# MMC1 register map
Vendor: Texas Instruments
Registers are 32-bit, access per field, reset 0x0 unless marked. A register's access mark holds for its fields unless they carry their own. Offsets are as the file gives them; [hi:lo] are bit positions; 'fields as' and 'values as' point back to an identical list.

## MMC1 (part 3 of 3)
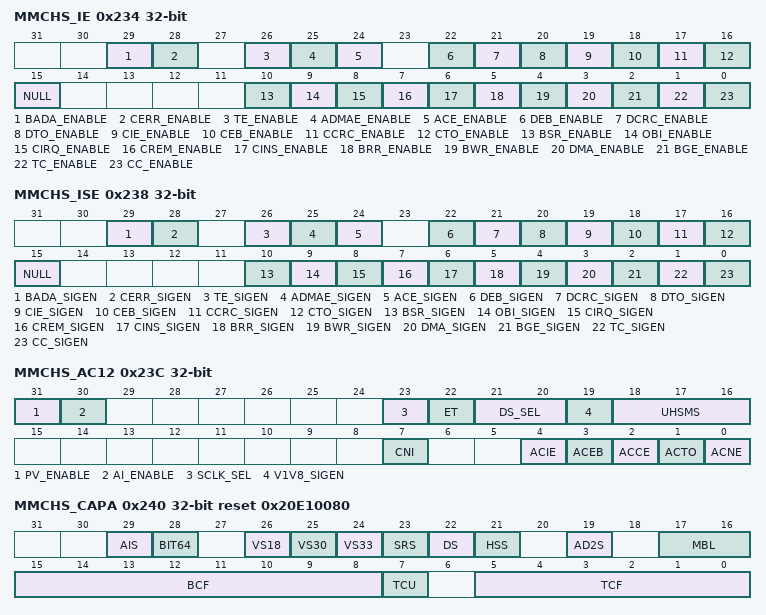
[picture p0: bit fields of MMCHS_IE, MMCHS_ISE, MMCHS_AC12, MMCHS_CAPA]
0x234 MMCHS_IE — Interrupt Status Enable Register This register allows to enable/disable the module to set status bits, on an event-by-event basis. [31:16] = Error Interrupt Status Enable [15:0] = Normal Interrupt Status Enable
  [29] BADA_ENABLE rw — Bad access to data space Status Enable
    0=Masked; 1=Enabled
  [28] CERR_ENABLE rw — Card Error Status Enable
    0=Masked; 1=Enabled
  [26] TE_ENABLE rw — Tuning Error Status Enable
    0=Masked; 1=Enabled
  [25] ADMAE_ENABLE rw — ADMA Error Status Enable
    0=Masked; 1=Enabled
  [24] ACE_ENABLE rw — Auto CMD Error Status Enable
    0=Masked; 1=Enabled
  [22] DEB_ENABLE rw — Data End Bit Error Status Enable
    0=Masked; 1=Enabled
  [21] DCRC_ENABLE rw — Data CRC Error Status Enable
    0=Masked; 1=Enabled
  [20] DTO_ENABLE rw — Data Timeout Error Status Enable
    0=Masked (The data timeout detection is deactivated. The host controller provides the clock to the card until the card sends the data or the transfer is aborted.); 1=Enabled (The data timeout detection is enabled.)
  [19] CIE_ENABLE rw — Command Index Error Status Enable
    0=Masked; 1=Enabled
  [18] CEB_ENABLE rw — Command End Bit Error Status Enable
    0=Masked; 1=Enabled
  [17] CCRC_ENABLE rw — Command CRC Error Status Enable
    0=Masked; 1=Enabled
  [16] CTO_ENABLE rw — Command Timeout Error Status Enable
    0=Masked; 1=Enabled
  [15] NULL ro — Fixed to 0 The host driver shall control error interrupts using the Error Interrupt Signal Enable register. Writes to this bit are ignored
  [10] BSR_ENABLE rw — Boot Status Enable A write to this register when MMCHS_CON[BOOT_ACK] is set to 0x0 is ignored.
    0=Masked; 1=Enabled
  [9] OBI_ENABLE rw — Out-of-Band Status Enable A write to this register when MMCHS_CON[OBIE] is set to '0' is ignored.
    0=Masked; 1=Enabled
  [8] CIRQ_ENABLE rw — Card Status Enable A clear of this bit also clears the corresponding status bit. During 1-bit mode, if the interrupt routine doesn't remove the source of a card interrupt in the SDIO card, the status bit is reasserted when this bit is set to 1.
    0=Masked; 1=Enabled
  [7] CREM_ENABLE rw — Card Removal Status Enable
    0=Masked; 1=Enabled
  [6] CINS_ENABLE rw — Card Insertion Status Enable
    0=Masked; 1=Enabled
  [5] BRR_ENABLE rw — Buffer Read Ready Status Enable
    0=Masked; 1=Enabled
  [4] BWR_ENABLE rw — Buffer Write Ready Status Enable
    0=Masked; 1=Enabled
  [3] DMA_ENABLE rw — DMA Status Enable
    0=Masked; 1=Enabled
  [2] BGE_ENABLE rw — Block Gap Event Status Enable
    0=Masked; 1=Enabled
  [1] TC_ENABLE rw — Transfer Complete Status Enable
    0=Masked; 1=Enabled
  [0] CC_ENABLE rw — Command Complete Status Enable
    0=Masked; 1=Enabled
0x238 MMCHS_ISE — Interrupt Signal Enable Register This register allows to enable/disable the module internal sources of status, on an event-by-event basis. [31:16] = Error Interrupt Signal Enable [15:0] = Normal Interrupt Signal Enable
  [29] BADA_SIGEN rw — Bad access to data space Signal Enable
    0=Masked; 1=Enabled
  [28] CERR_SIGEN rw — Card Error Interrupt Signal Enable
    0=Masked; 1=Enabled
  [26] TE_SIGEN rw — Tuning Error Signal Enable
    0=Masked; 1=Enabled
  [25] ADMAE_SIGEN rw — ADMA Error Signal Enable
    0=Masked; 1=Enabled
  [24] ACE_SIGEN rw — Auto CMD Error Signal Enable
    0=Masked; 1=Enabled
  [22] DEB_SIGEN rw — Data End Bit Error Signal Enable
    0=Masked; 1=Enabled
  [21] DCRC_SIGEN rw — Data CRC Error Signal Enable
    0=Masked; 1=Enabled
  [20] DTO_SIGEN rw — Data Timeout Error Signal Enable
    0=Masked; 1=Enabled
  [19] CIE_SIGEN rw — Command Index Error Signal Enable
    0=Masked; 1=Enabled
  [18] CEB_SIGEN rw — Command End Bit Error Signal Enable
    0=Masked; 1=Enabled
  [17] CCRC_SIGEN rw — Command CRC Error Signal Enable
    0=Masked; 1=Enabled
  [16] CTO_SIGEN rw — Command timeout Error Signal Enable
    0=Masked; 1=Enabled
  [15] NULL ro — Fixed to 0 The host driver shall control error interrupts using the Error Interrupt Signal Enable register. Writes to this bit are ignored
  [10] BSR_SIGEN rw — Boot Status Signal Enable A write to this register when MMCHS_CON[BOOT_ACK] is set to 0x0 is ignored.
    0=Masked; 1=Enabled
  [9] OBI_SIGEN rw — Out-Of-Band Interrupt Signal Enable A write to this register when MMCHS_CON[OBIE] is set to '0' is ignored.
    0=Masked; 1=Enabled
  [8] CIRQ_SIGEN rw — Card Interrupt Signal Enable
    0=Masked; 1=Enabled
  [7] CREM_SIGEN rw — Card Removal Signal Enable
    0=Masked; 1=Enabled
  [6] CINS_SIGEN rw — Card Insertion Signal Enable
    0=Masked; 1=Enabled
  [5] BRR_SIGEN rw — Buffer Read Ready Signal Enable
    0=Masked; 1=Enabled
  [4] BWR_SIGEN rw — Buffer Write Ready Signal Enable
    0=Masked; 1=Enabled
  [3] DMA_SIGEN rw — DMA Interrupt Signal Enable
    0=Masked; 1=Enabled
  [2] BGE_SIGEN rw — Black Gap Event Signal Enable
    0=Masked; 1=Enabled
  [1] TC_SIGEN rw — Transfer Completed Status Enable
    0=Masked; 1=Enabled
  [0] CC_SIGEN rw — Command Complete Status Enable
    0=Masked; 1=Enabled
0x23C MMCHS_AC12 — Host Control 2 Register and Auto CMD Error Status Register This register is used to indicate CMD12 response error of Auto CMD12 and CMD23 response error of Auto CMD23. The Host driver can determine what kind of Auto CMD12 / CMD23 errors occur by this register. Auto CMD23 errors are indicated only in bits[4:1]. Bits[7:0] are valid only when the [3:2] ACEN bitfield is configured to enable Auto CMD and the Auto CMD Error bit ([24]ACE) is set.
  [31] PV_ENABLE rw — Preset Value Enable Host Controller Version 3.00 supports this bit. As the operating SDCLK frequency and I/O driver strength depend on the Host System implementation, it is difficult to determine these parameters in the Standard Host Driver. When Preset Value Enable is set, automatic SDCLK frequency generation and driver strength selection is performed without considering system specific conditions. This bit enables the functions defined in the Preset Value registers, see, . If this bit is set to 0, MMCHS_SYSCTL[15:6] CLKD, MMCHS_SYSCTL[5] CGS and MMCHS_AC12[21:20] DS_SEL are set by Host Driver. If this bit is set to 1, MMCHS_SYSCTL[15:6] CLKD, MMCHS_SYSCTL[5] CGS and MMCHS_AC12[21:20] DS_SEL are set by Host Controller as specified in the Preset Value registers, see, .
    0=Disabled (SDCLK and Driver Strength (DS_SEL) are controlled by Host Driver.); 1=Enabled (Automatic Selection by Preset Value are Enabled.)
  [30] AI_ENABLE rw — Asynchronous Interrupt Enable This bit can be set to 1 if a card supports asynchronous interrupts and MMCHS_CAPA[29] AIS is set to 1. Asynchronous interrupt is effective when DAT[1] interrupt is used in 4-bit SD mode (and zero is set to Interrupt Pin Select in the Shared Bus Control register). If this bit is set to 1, the Host Driver can stop the SDCLK during asynchronous interrupt period to save power. During this period, the Host Controller continues to deliver the Card Interrupt to the host when it is asserted by the Card.
    0=Disabled; 1=Enabled
  [23] SCLK_SEL rw — Sampling Clock Select Host Controller uses this bit to select sampling clock to receive CMD and DAT. This bit is set by tuning procedure and valid after the completion of tuning (when MMCHS_AC12[22] ET is cleared). Setting 1 means that tuning is completed successfully and setting 0 means that tuning is failed. Writing 1 to this bit is meaningless and ignored. A tuning circuit is reset by writing to 0. This bit can be cleared with setting MMCHS_AC12[22] ET. Once the tuning circuit is reset, it will take time to complete tuning sequence. Therefore, Host Driver should keep this bit to 1 to perform re-tuning sequence to compete re-tuning sequence in a short time. Change of this bit is not allowed while the Host Controller is receiving response or a read data block.
    0=Fixed clock is used to sample data; 1=Tuned clock is used to sample data
  [22] ET rw — Execute Tuning This bit is set to 1 to start tuning procedure and automatically cleared when tuning procedure is completed. The result of tuning is indicated to MMCHS_AC12[23] SCLK_SEL. Tuning procedure is aborted by writing 0. This is Read-Write with automatic clear register
    0=Completed (Not Tuned or Tuning Completed); 1=Execute Tuning
  [21:20] DS_SEL rw — Driver Strength Select Host Controller output driver in 1.8V signaling is selected by this bit. In 3.3V signaling, this field is not effective. This field can be set depending on Driver Type A, C and D support bits (DTA, DTC and DTD respectively) in the MMCHS_CAPA2 register. This bit depends on setting of Preset Value Enable. If Preset Value Enable = 0, this field is set by Host Driver. If Preset Value Enable = 1, this field is automatically set by a value specified in the one of Preset Value registers, see, .
    0=DTB (Driver Type B is selected (Default)); 1=DTA (Driver Type A is selected); 3=DTD (Driver Type D is selected); 2=DTC (Driver Type C is selected)
  [19] V1V8_SIGEN rw — 1.8V Signaling Enable This bit controls voltage regulator for I/O cell. 3.3V is supplied to the card regardless of signaling voltage. Setting this bit from 0 to 1 starts changing signal voltage from 3.3V to 1.8V. 1.8V regulator output shall be stable within 5ms. Host Controller clears this bit if switching to 1.8V signaling fails. Clearing this bit from 1 to 0 starts changing signal voltage from 1.8V to 3.3V. 3.3V regulator output shall be stable within 5ms. Host Driver can set this bit to 1 when Host Controller supports 1.8V signaling (One of support bits is set to 1: SDR50, SDR104 or DDR50 in MMCHS_CAPA2 register) and the card or device supports UHS-I (S18A=1. Refer to Bus Signal Voltage Switch Sequence in the Physical Layer Specification Version 3.0x).
    0=3V3 (3.3V Signaling); 1=1V8 (1.8V Signaling)
  [18:16] UHSMS rw — UHS Mode Select This field is used to select one of UHS-I modes or eMMC HS200 mode and is effective when 1.8V Signaling Enable is set to 1. If MMCHS_AC12[31] PV_ENABLE is set to 1, Host Controller sets MMCHS_SYSCTL[15:6] CLKD, MMCHS_SYSCTL[5] CGS and MMCHS_AC12[21:20] DS_SEL according to Preset Value registers, see, . In this case, one of preset value registers is selected by this field. Host Driver needs to reset MMCHS_SYSCTL[2] CEN before changing this field to avoid generating clock glitch. After setting this field, Host Driver sets MMCHS_SYSCTL[2] CEN again. When SDR50, SDR104 or DDR50 is selected for SDIO card, interrupt detection at the block gap shall not be used. Read Wait timing is changed for these modes. Refer to the SDIO Specification Version 3.00 for more detail.
    0=SDR12; 1=SDR25; 2=SDR50; 3=SDR104_HS200; 4=DDR50
  [7] CNI ro — Command Not Issued By Auto CMD12 Error Setting this bit to 1 means CMD_wo_DAT is not executed due to an Auto CMD12 Error (D04-D01) in this register. This bit is set to 0 when Auto CMD Error is generated by Auto CMD23.
    1=CmdNI (Command not issued); 0=No error
  [4] ACIE ro — Auto CMD Index Error - For Auto CMD12 and Auto CMD23 This bit is set if the Command Index error occurs in response to a command.
    1=Err (Error); 0=No error
  [3] ACEB ro — Auto CMD End Bit Error - For Auto CMD12 and Auto CMD23 This bit is set when detecting that the end bit of command response is 0.
    1=Err (End bit Error Generated); 0=No error
  [2] ACCE ro — Auto CMD CRC Error - For Auto CMD12 and Auto CMD23 This bit is set when detecting a CRC error in the command response.
    1=Err (CRC Error Generated); 0=No error
  [1] ACTO ro — Auto CMD Timeout Error - For Auto CMD12 and Auto CMD23 This bit is set if no response is returned within 64 SDCLK cycles from the end bit of command. If this bit is set to1, the other error status bits (D04-D02) are meaningless.
    1=TimeOut (Auto CMD Time Out); 0=No error
  [0] ACNE ro — Auto CMD12 Not Executed If memory multiple block data transfer is not started due to command error, this bit is not set because it is not necessary to issue Auto CMD12. Setting this bit to 1 means the Host Controller cannot issue Auto CMD12 to stop memory multiple block data transfer due to some error. If this bit is set to 1, other error status bits (D04-D01) are meaningless. This bit is set to 0 when Auto CMD Error is generated by Auto CMD23.
    1=NotExe (Auto CMD12 Not Executed); 0=Exe (Auto CMD12 Executed)
0x240 MMCHS_CAPA reset 0x20E10080 — Capabilities Register This register lists the capabilities of the MMC/SD/SDIO host controller.
  [29] AIS ro — Asynchronous Interrupt Support Refer to SDIO Specification Version 3.00 about asynchronous interrupt.
    1=AIS_Sup (Asynchronous Interrupt Supported); 0=AIS_NotSup (Asynchronous Interrupt Not Supported)
  [28] BIT64 ro — 64 Bit System Bus Support Setting 1 to this bit indicates that the Host Controller supports 64-bit address descriptor mode and is connected to 64-bit address system bus.
    1=SysAddr64b (64 bit System bus address); 0=SysAddr32b (32 bit System bus address)
  [26] VS18 rw — Voltage support 1.8V Initialization of this register (via a write access to this register) depends on the system capabilities. The host driver shall not modify this register after the initilaization. This register is only reinitialized by a hard reset (via RESETN signal)
    0=St_1V8NotSup_w (1.8V Not supported); 1=St_1V8Sup_w (1.8V Supported); 1=1V8_Sup_r (1.8V Supported); 0=1V8_NotSup_r (1.8V Not Supported)
  [25] VS30 rw — Voltage support 3.0V Initialization of this register (via a write access to this register) depends on the system capabilities. The host driver shall not modify this register after the initilaization. This register is only reinitialized by a hard reset (via RESETN signal)
    0=St_3V0NotSup_w (3.0V Not supported); 1=St_3V0Sup_w (3.0V Supported); 1=3V0_Sup_r (3.0V Supported); 0=3V0_NotSup_r (3.0V Not Supported)
  [24] VS33 rw — Voltage support 3.3V Initialization of this register (via a write access to this register) depends on the system capabilities. The host driver shall not modify this register after the initilaization. This register is only reinitialized by a hard reset (via RESETN signal)
    0=St_3V3NotSup_w (3.3V Not supported); 1=St_3V3Sup_w (3.3V Supported); 1=3V3_Sup_r (3.3V Supported); 0=3V3_NotSup_r (3.3V Not Supported)
  [23] SRS ro — Suspend/Resume support (SDIO cards only) This bit indicates whether the host controller supports Suspend/Resume functionality.
    1=Supported (The Host controller supports Suspend/Resume functionality.); 0=NotSupported (The Host controller does not Suspend/Resume functionality.)
  [22] DS ro — DMA support This bit indicates that the Host Controller is able to use DMA to transfer data between system memory and the Host Controller directly.
    1=Supported (DMA Supported); 0=NotSupported (DMA Not Supported)
  [21] HSS ro — High speed support This bit indicates that the host controller supports high speed operations and can supply an up-to maximum card frequency.
    1=Supported (High Speed Supported); 0=NotSupported (High Speed Not Supported NOTE: High Speed modes are supported, but)
  [19] AD2S ro — ADMA2 Support This bit indicates whether the Host Controller is capable of using ADMA2. It depends on setting of generic parameter MADMA_EN
    1=ADMA2Supported; 0=ADMA2NotSupported
  [17:16] MBL ro — Maximum block length This value indicates the maximum block size that the host driver can read and write to the buffer in the host controller. This value depends on definition of generic parameter with a max value of 2048 bytes. The host controller supports 512 bytes and 1024 bytes block transfers.
    2=MBL_2_r (2048 bytes); 1=MBL_1_r (1024 bytes); 0=MBL_0_r (512 bytes)
  [15:8] BCF ro — Base Clock Frequency For SD Clock This value indicates the base (maximum) clock frequency for the SD Clock. 8-bit Base Clock Frequency This mode is supported by the Host Controller Version 3.00. Unit values are 1MHz. The supported clock range is 10MHz to 255MHz. FFh : 255MHz .... : ....... 02h : 2MHz 01h : 1MHz 00h : Get information via another method If the real frequency is 16.5MHz, the lager value shall be set 0001 0001b (17MHz) because the Host Driver use this value to calculate the clock divider value (Refer to MMCHS_SYSCTL[15:6] CLKD) and it shall not exceed upper limit of the SD Clock frequency. If these bits are all 0, the Host System has to get information via another method.
    0=OMeth (The value indicating the base (maximum) frequency for the output clock provided to the card is system dependent and is not available in this register. Get the information via another method.)
  [7] TCU ro — Timeout clock unit This bit shows the unit of base clock frequency used to detect Data Timeout Error (MMCHS_STAT[DTO]).
    1=KHz (MHz); 0=MHz (KHz)
  [5:0] TCF ro — Timeout clock frequency The timeout clock frequency is used to detect Data Timeout Error (MMCHS_STAT[DTO]).
    0=OMeth (The timeout clock frequency depends on the frequency of the clock provided to the card. The value of the timeout clock frequency is not available in this register.)
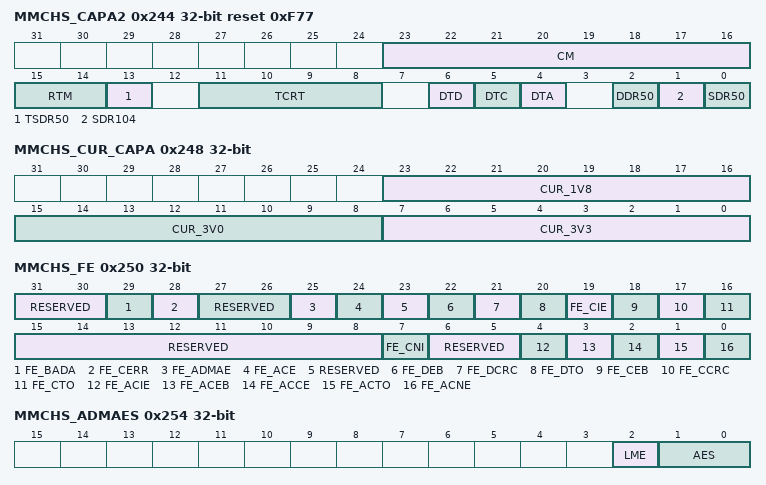
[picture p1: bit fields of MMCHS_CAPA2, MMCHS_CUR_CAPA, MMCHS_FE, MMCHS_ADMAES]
0x244 MMCHS_CAPA2 ro reset 0xF77 — Capabilities 2 Register This register provides the Host Driver with information specific to the Host Controller implementation. The Host Controller may implement these values as fixed or loaded from flash memory during power on initialization. Refer to Software Reset For All in the Software Reset register for loading from flash memory and completion timing control.
  [23:16] CM — Clock Multiplier This field indicates clock multiplier value of programmable clock generator. Refer to MMCHS_SYSCTL [15:0]. Setting 00h means that Host Controller does not support programmable clock generator. 00h : Clock Multiplier is Not Supported 01h : Clock Multiplier M = 2 02h : Clock Multiplier M = 3 .... : ...................... FFh : Clock Multiplier M = 256
  [15:14] RTM — Re-Tuning Modes This field selects re-tuning method and limits the maximum data length. Bit47-46 Re-Tuning Mode Re-Tuning Method Data Length There are two re-tuning timings: Re-Tuning Request controlled by the Host Controller and expiration of a Re-Tuning Timer controlled by the Host Driver. By receiving either timing, the Host Driver executes the re-tuning procedure just before a next command issue. The maximum data length per read/write command is restricted so that re-tuning procedures can be inserted during data transfers. (1) Re-Tuning Mode 1 The host controller does not have any internal logic to detect when the re-tuning needs to be performed. In this case, the Host Driver should maintain all re-tuning timings by using a Re-Tuning Timer. To enable inserting the re-tuning procedure during data transfers, the data length per read/write command shall be limited up to 4 MiB. (2) Re-Tuning Mode 2 The host controller has the capability to indicate the re-tuning timing by Re-Tuning Request during data transfers. Then the data length per read/write command shall be limited up to 4 MiB. During non data transfer, re-tuning timing is determined by either Re-Tuning Request or Re-Tuning Timer. If Re-Tuning Request is used, Re-Tuning Timer should be disabled. (3) Re-Tuning Mode 3 The host controller has the capability to take care of the re-tuning during data transfer (Auto Re-Tuning). Re-Tuning Request shall not be generated during data transfers and there is no limitation to data length per read/write command. During non data transfer, re-tuning timing is determined by either Re-Tuning Request or Re-Tuning Timer. If Re-Tuning Request is used, Re-Tuning Timer should be disabled. Re-Tuning Timer Control Example for Re-Tuning Mode 1 The initial value of re-tuning timer is provided by Timer Count for Re-Tuning field in this register. The timer starts counting by loading the initial value. When the timer expires, the Host Driver marks an expiration flag. On receiving a command request, the Host driver checks the expiration flag. If the expiration flag is set, then the Host Driver should perform the re-tuning procedure before issuing a command. If the expiration flag is not set, then the Host Driver issues a command without performing the re-tuning procedure. Every time the re-tuning procedure is performed, the timer loads the new initial value and the expiration flag is cleared. Re-Tuning Timer Control Example for Re-Tuning Mode 2 and Mode 3 The timer control is almost the same as Re-Tuning Mode 1 except the timer loads the new initial value after data transfer (when receiving Transfer Complete). In case of Mode 3, Timer Count for Re-Tuning is set either smaller value: Tuning effective time after re-tuning procedure or after data transfer. If a Host System goes into power down mode, the Host Driver should stop the re-tuning timer and set the expiration flag to 1 when the Host System resumes from power down mode.
    2=Mode3 (Auto Re-Tuning (for transfer) - Timer and Re-Tuning Request); 1=Mode2 (Timer and Re-Tuning Request - Max data length 4 MiB); 0=Mode1 (Timer - Max data length 4 MiB)
  [13] TSDR50 — Use Tuning for SDR50 If this bit is set to 1, this Host Controller requires tuning to operate SDR50. (Tuning is always required to operate SDR104.)
    1=Required (SDR50 requires tuning.); 0=NotRequired (SDR50 does not require tuning.)
  [11:8] TCRT — Timer Count for Re-Tuning This field indicates an initial value of the Re-Tuning Timer for Re-Tuning Mode 1 to 3. Setting to 0 disables Re-Tuning Timer.
    3=TCRT_3_r (4 seconds); 4=TCRT_4_r (8 seconds); 11=TCRT_11_r (1024 seconds); 15=OtherSource (Get information from other source); 2=TCRT_2_r (2 seconds); 0=Disabled (Re-Tuning Timer disabled); 10=TCRT_10_r (512 seconds); 6=TCRT_6_r (32 seconds); 1=TCRT_1_r (1 second); 8=TCRT_8_r (128 seconds); 7=TCRT_7_r (64 seconds); 9=TCRT_9_r (256 seconds); 5=TCRT_5_r (16 seconds)
  [6] DTD — Driver Type D Support This bit indicates support of Driver Type D for 1.8 Signaling.
    1=Supported (Driver Type D is Supported); 0=NotSupported (Driver Type D is Not Supported.)
  [5] DTC — Driver Type C Support This bit indicates support of Driver Type C for 1.8 Signaling.
    1=Supported (Driver Type C is Supported.); 0=NotSupported (Driver Type C is Not Supported.)
  [4] DTA — Driver Type A Support This bit indicates support of Driver Type A for 1.8 Signaling.
    1=Supported (Driver Type A is Supported.); 0=NotSupported (Driver Type A is Not Supported.)
  [2] DDR50 — DDR50 Support
    1=Supported (DDR50 is Supported.); 0=NotSupported (DDR50 is Not Supported.)
  [1] SDR104 — SDR104 Support SDR104 requires tuning.
    1=Supported (SDR104 is Supported.); 0=NotSupported (SDR104 is Not Supported.)
  [0] SDR50 — SDR50 Support If SDR104 is supported, this bit shall be set to 1. Bit 13 indicates whether SDR50 requires tuning or not.
    1=Supported (SDR50 is Supported.); 0=NotSupported (SDR50 is Not Supported.)
0x248 MMCHS_CUR_CAPA — Maximum Current Capabilities Register This register indicates the maximum current capability for each voltage. The value is meaningful if the voltage support is set in the capabilities register (). Initialization of this register (via a write access to this register) depends on the system capabilities. The host driver shall not modify this register after the initilaization. This register is only reinitialized by a hard reset (via RESETN signal)
  [all] fields
    0=OMeth (The maximum current capability for this voltage is not available. Feature not implemented.)
  [23:16] CUR_1V8 rw — Maximum current for 1.8V
  [15:8] CUR_3V0 rw — Maximum current for 3.0V
  [7:0] CUR_3V3 rw — Maximum current for 3.3V
0x250 MMCHS_FE access not given — Force Event Register for Auto CMD Error Status and Error Interrupt status The Force Event Register is not a physically implemented register. Rather, it is an address at which the Auto CMD Error Status Register () can be written. Writing 1 : set each bit of the Auto CMD Error Status Register Writing 0 : no effect Rather, it is an address at which the Error Interrupt Status register can be written. The effect of a write to this address will be reflected in the Error Interrupt Status Register if the corresponding bit of the Error Interrupt Status Enable Register is set. Writing 1 : set each bit of the Error Interrupt Status Register Writing 0 : no effect Note: By setting this register, the Error Interrupt can be set in the Error Interrupt Status register. In order to generate interrupt signal, both the Error Interrupt Status Enable and Error Interrupt Signal Enable shall be set.
  [31:30] RESERVED — (access NA)
  [29] FE_BADA wo — Force Event Bad access to data space.
    0=NoAction (No effect, No Interrupt.); 1=IntForced (Interrupt Forced)
  [28] FE_CERR wo — Force Event Card error.
    values as FE_BADA
  [27:26] RESERVED — (access NA)
  [25] FE_ADMAE wo — Force Event ADMA Error.
    values as FE_BADA
  [24] FE_ACE wo — Force Event for Auto CMD Error - For Auto CMD12 and Auto CMD23
    values as FE_BADA
  [23] RESERVED — (access NA)
  [22] FE_DEB wo — Force Event Data End Bit error.
    values as FE_BADA
  [21] FE_DCRC wo — Force Event Data CRC Error.
    values as FE_BADA
  [20] FE_DTO wo — Force Event Data Timeout Error.
    values as FE_BADA
  [19] FE_CIE wo — Force Event Command Index Error.
    values as FE_BADA
  [18] FE_CEB wo — Force Event Command End Bit Error.
    values as FE_BADA
  [17] FE_CCRC wo — Force Event Command CRC Error.
    values as FE_BADA
  [16] FE_CTO wo — Command Timeout Error This bit is set automatically when no response is received within 64 clock cycles from the end bit of the command. For commands that reply within 5 clock cycles - the timeout is still detected at 64 clock cycles.
    0=St_un_w (Status bit unchanged); 1=St_rst_w (Status is cleared)
  [15:8] RESERVED — (access NA)
  [7] FE_CNI wo — Force Event Command not issue by Auto CMD12 error
    values as FE_BADA
  [6:5] RESERVED — (access NA)
  [4] FE_ACIE wo — Force Event for Auto CMD Index Error - For Auto CMD12 and Auto CMD23
    values as FE_BADA
  [3] FE_ACEB wo — Force Event Auto CMD End Bit Error
    values as FE_BADA
  [2] FE_ACCE wo — Force Event Auto CMD CRC Error
    values as FE_BADA
  [1] FE_ACTO wo — Force Event Auto CMD Timeout Error
    values as FE_BADA
  [0] FE_ACNE wo — Force Event Auto CMD12 Not Executed
    values as FE_BADA
0x254 MMCHS_ADMAES — ADMA Error Status Register When ADMA Error Interrupt is occurred, the ADMA Error States field in this register holds the ADMA state and the ADMA System Address Register holds the address around the error descriptor. For recovering the error, the Host Driver requires the ADMA state to identify the error descriptor address as follows: ST_STOP: Previous location set in the ADMA System Address register is the error descriptor address ST_FDS: Current location set in the ADMA System Address register is the error descriptor address ST_CADR: This sate is never set because do not generate ADMA error in this state. ST_TFR: Previous location set in the ADMA System Address register is the error descriptor address In case of write operation, the Host Driver should use ACMD22 to get the number of written block rather than using this information, since unwritten data may exist in the Host Controller. The Host Controller generates the ADMA Error Interrupt when it detects invalid descriptor data (Valid=0) at the ST_FDS state. In this case, ADMA Error State indicates that an error occurs at ST_FDS state. The Host Driver may find that the Valid bit is not set in the error descriptor.
  [2] LME rw — ADMA Length Mismatch Error: (1) While Block Count Enable being set, the total data length specified by the Descriptor table is different from that specified by the Block Count and Block Length. (2) Total data length can not be divided by the block length.
    0=NoError; 1=Error
  [1:0] AES rw — ADMA Error State This field indicates the state of ADMA when error occurred during ADMA data transfer. This field will never be 0x2 because ADMA never stops in that state. 0x0: ST_STOP (STOP_ADMA). Previous SYS_ADR is the error descriptor address 0x1: ST_FDS (Fetch Descriptor). Content of current SYS_ADR is the error descriptor address 0x2: Not used. Error never set in this state 0x3: ST_TFR (Transfer Data). Previous SYS_ADR is the error descriptor address
0x258 MMCHS_ADMASAL rw — ADMA System address Low bits
  [31:0] ADMA_A32B — ADMA System address 32 bits.This register holds byte address of executing command of the Descriptor table. 32-bit Address Descriptor uses lower 32-bit of this register. At the start of ADMA, the Host Driver shall set start address of the Descriptor table. The ADMA increments this register address, which points to next line, when every fetching a Descriptor line. When the ADMA Error Interrupt is generated, this register shall hold valid Descriptor address depending on the ADMA state. The Host Driver shall program Descriptor Table on 32-bit boundary and set 32-bit boundary address to this register. ADMA2 ignores lower 2-bit of this register and assumes it to be 00b.
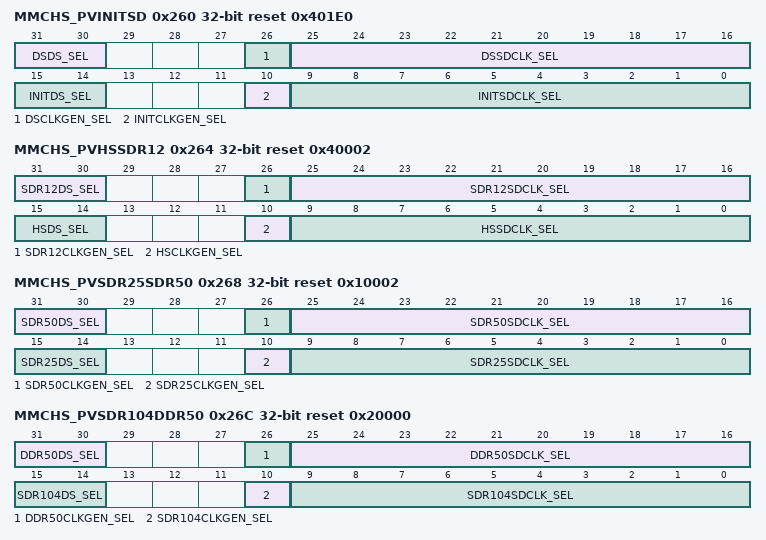
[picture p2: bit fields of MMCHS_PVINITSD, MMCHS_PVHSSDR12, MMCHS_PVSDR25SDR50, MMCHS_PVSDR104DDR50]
0x260 MMCHS_PVINITSD ro reset 0x401E0 — Preset Value for Initialization and Default Speed modes
  [31:30] DSDS_SEL — Driver Strength Select Value - Default Speed mode Driver Strength is supported by 1.8V signaling bus speed modes. This field is meaningless for 3.3V signaling.
    3=DTD (Driver Type D is Selected.); 2=DTC (Driver Type C is Selected.); 1=DTA (Driver Type A is Selected.); 0=DTB (Driver Type B is Selected.)
  [26] DSCLKGEN_SEL — Clock Generator Select Value - Default Speed mode This bit is effective when Host Controller supports programmable clock generator.
    1=Programmable Clock Generator; 0=Host Controller Ver2.00 Compatible Clock Generator
  [25:16] DSSDCLK_SEL — SDCLK Frequency Select Value - Default Speed mode 10-bit preset value to set MMCHS_SYSCTL[15:6] CLKD is described by a host system.
  [15:14] INITDS_SEL — Driver Strength Select Value - Initialization mode Driver Strength is supported by 1.8V signaling bus speed modes. This field is meaningless for 3.3V signaling.
    3=DTD (Driver Type D is Selected); 2=DTC (Driver Type C is Selected); 1=DTA (Driver Type A is Selected); 0=DTB (Driver Type B is Selected)
  [10] INITCLKGEN_SEL — Clock Generator Select Value - Initialization mode This bit is effective when Host Controller supports programmable clock generator.
    values as DSCLKGEN_SEL
  [9:0] INITSDCLK_SEL — SDCLK Frequency Select Value - Initialization mode 10-bit preset value to set MMCHS_SYSCTL[15:6] CLKD is described by a host system.
0x264 MMCHS_PVHSSDR12 ro reset 0x40002 — Preset Value for High Speed and SDR12 speed modes
  [31:30] SDR12DS_SEL — Driver Strength Select Value - SDR12 mode Driver Strength is supported by 1.8V signaling bus speed modes. This field is meaningless for 3.3V signaling.
    values as MMCHS_PVINITSD.DSDS_SEL
  [26] SDR12CLKGEN_SEL — Clock Generator Select Value - SDR12 mode This bit is effective when Host Controller supports programmable clock generator.
    values as MMCHS_PVINITSD.DSCLKGEN_SEL
  [25:16] SDR12SDCLK_SEL — SDCLK Frequency Select Value - SDR12 mode 10-bit preset value to set MMCHS_SYSCTL[15:6] CLKD is described by a host system.
  [15:14] HSDS_SEL — Driver Strength Select Value - High Speed mode Driver Strength is supported by 1.8V signaling bus speed modes. This field is meaningless for 3.3V signaling.
    values as MMCHS_PVINITSD.DSDS_SEL
  [10] HSCLKGEN_SEL — Clock Generator Select Value - High Speed mode This bit is effective when Host Controller supports programmable clock generator.
    values as MMCHS_PVINITSD.DSCLKGEN_SEL
  [9:0] HSSDCLK_SEL — SDCLK Frequency Select Value - High Speed mode 10-bit preset value to set MMCHS_SYSCTL[15:6] CLKD is described by a host system.
0x268 MMCHS_PVSDR25SDR50 ro reset 0x10002 — Preset Value for SDR25 and SDR50 speed modes
  [31:30] SDR50DS_SEL — Driver Strength Select Value - SDR50 mode Driver Strength is supported by 1.8V signaling bus speed modes. This field is meaningless for 3.3V signaling.
    values as MMCHS_PVINITSD.DSDS_SEL
  [26] SDR50CLKGEN_SEL — Clock Generator Select Value - SDR50 mode This bit is effective when Host Controller supports programmable clock generator.
    values as MMCHS_PVINITSD.DSCLKGEN_SEL
  [25:16] SDR50SDCLK_SEL — SDCLK Frequency Select Value - SDR50 mode 10-bit preset value to set MMCHS_SYSCTL[15:6] CLKD is described by a host system.
  [15:14] SDR25DS_SEL — Driver Strength Select Value - SDR25 mode Driver Strength is supported by 1.8V signaling bus speed modes. This field is meaningless for 3.3V signaling.
    values as MMCHS_PVINITSD.DSDS_SEL
  [10] SDR25CLKGEN_SEL — Clock Generator Select Value - SDR25 mode This bit is effective when Host Controller supports programmable clock generator.
    1=Programmable Clock Generato; 0=Host Controller Ver2.00 Compatible Clock Generator
  [9:0] SDR25SDCLK_SEL — SDCLK Frequency Select Value - SDR25 mode 10-bit preset value to set MMCHS_SYSCTL[15:6] CLKD is described by a host system.
0x26C MMCHS_PVSDR104DDR50 ro reset 0x20000 — Preset Value for SDR104 and DDR50 speed modes
  [31:30] DDR50DS_SEL — Driver Strength Select Value - DDR50 mode Driver Strength is supported by 1.8V signaling bus speed modes. This field is meaningless for 3.3V signaling.
    values as MMCHS_PVINITSD.DSDS_SEL
  [26] DDR50CLKGEN_SEL — Clock Generator Select Value - DDR50 mode This bit is effective when Host Controller supports programmable clock generator.
    values as MMCHS_PVINITSD.DSCLKGEN_SEL
  [25:16] DDR50SDCLK_SEL — SDCLK Frequency Select Value - DDR50 mode 10-bit preset value to set MMCHS_SYSCTL[15:6] CLKD is described by a host system.
  [15:14] SDR104DS_SEL — Driver Strength Select Value - SDR104 mode Driver Strength is supported by 1.8V signaling bus speed modes. This field is meaningless for 3.3V signaling.
    values as MMCHS_PVINITSD.DSDS_SEL
  [10] SDR104CLKGEN_SEL — Clock Generator Select Value - SDR104 mode This bit is effective when Host Controller supports programmable clock generator.
    values as MMCHS_PVINITSD.DSCLKGEN_SEL
  [9:0] SDR104SDCLK_SEL — SDCLK Frequency Select Value - SDR104 mode 10-bit preset value to set MMCHS_SYSCTL[15:6] CLKD is described by a host system.
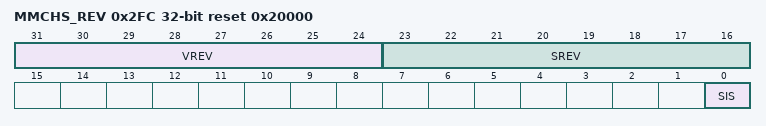
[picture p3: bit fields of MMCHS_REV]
0x2FC MMCHS_REV ro reset 0x20000 (reset mask 0xFFFFFF) — Versions Register This register contains the hard coded RTL vendor revision number, the version number of SD specification compliancy and a slot status bit. [31:16] = Host controller version [15:0] = Slot Interrupt Status
  [31:24] VREV — Vendor Version Number: IP revision [7:4] Major revision [3:0] Minor revision Examples: 0x10 for 1.0 0x21 for 2.1
  [23:16] SREV — Specification Version Number This status indicates the Host Controller Spec. Version. The upper and lower 4-bits indicate the version.
    3=Other (Reserved); 2=Ver3 (SD Host Specification Version 3.00.); 1=Ver2 (SD Host Specification Version 2.00 - Including the feature of the ADMA and Test Register.); 0=Ver1 (SD Host Specification Version 1.00.)
  [0] SIS — Slot Interrupt Status This status bit indicates the inverted state of interrupt signal for the module. By a power on reset or by setting a software reset for all (MMCHS_HCTL[SRA]), the interrupt signal shall be de-asserted and this status shall read 0.
